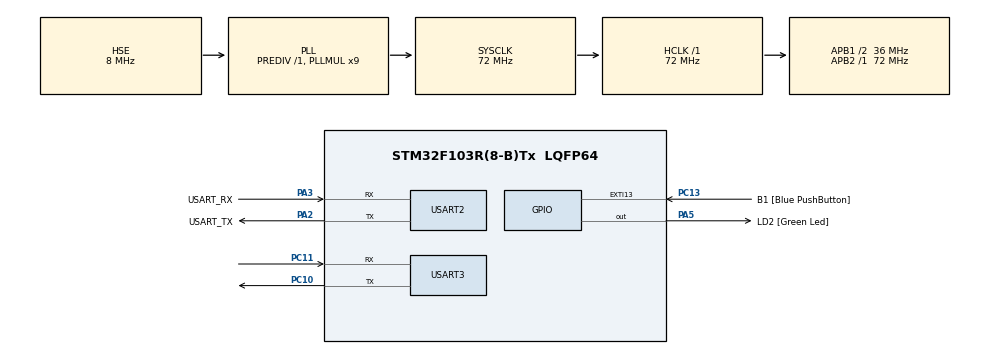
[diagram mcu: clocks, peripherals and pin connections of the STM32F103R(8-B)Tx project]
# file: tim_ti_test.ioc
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Dma.Request0=USART3_RX
Dma.Request1=USART3_TX
Dma.USART3_RX.0.Direction=DMA_PERIPH_TO_MEMORY
Dma.USART3_RX.0.Instance=DMA1_Channel3
Dma.USART3_RX.0.MemDataAlignment=DMA_MDATAALIGN_BYTE
Dma.USART3_RX.0.MemInc=DMA_MINC_ENABLE
Dma.USART3_RX.0.Mode=DMA_NORMAL
Dma.USART3_RX.0.PeriphDataAlignment=DMA_PDATAALIGN_BYTE
Dma.USART3_RX.0.PeriphInc=DMA_PINC_DISABLE
Dma.USART3_RX.0.Priority=DMA_PRIORITY_LOW
Dma.USART3_TX.1.Direction=DMA_MEMORY_TO_PERIPH
Dma.USART3_TX.1.Instance=DMA1_Channel2
Dma.USART3_TX.1.MemDataAlignment=DMA_MDATAALIGN_BYTE
Dma.USART3_TX.1.MemInc=DMA_MINC_ENABLE
Dma.USART3_TX.1.Mode=DMA_NORMAL
Dma.USART3_TX.1.PeriphDataAlignment=DMA_PDATAALIGN_BYTE
Dma.USART3_TX.1.PeriphInc=DMA_PINC_DISABLE
Dma.USART3_TX.1.Priority=DMA_PRIORITY_LOW
Mcu.Family=STM32F1
Mcu.Name=STM32F103R(8-B)Tx
Mcu.Package=LQFP64
NVIC.DMA1_Channel2_IRQn=true\:0\:0\:false\:false\:true\:false
NVIC.DMA1_Channel3_IRQn=true\:0\:0\:false\:false\:true\:false
NVIC.EXTI15_10_IRQn=true\:0\:0\:false\:false\:true\:true
NVIC.PriorityGroup=NVIC_PRIORITYGROUP_4
NVIC.TIM1_UP_IRQn=true\:0\:0\:false\:false\:true\:true
NVIC.USART3_IRQn=true\:0\:0\:false\:false\:true\:true
PA13.GPIO_Label=TMS
PA13.Mode=Serial_Wire
PA13.Signal=SYS_JTMS-SWDIO
PA14.GPIO_Label=TCK
PA14.Mode=Serial_Wire
PA14.Signal=SYS_JTCK-SWCLK
PA2.GPIO_Label=USART_TX
PA2.GPIO_Mode=GPIO_MODE_AF_PP
PA2.GPIO_PuPd=GPIO_NOPULL
PA2.GPIO_Speed=GPIO_SPEED_FREQ_LOW
PA2.Mode=Asynchronous
PA2.Signal=USART2_TX
PA3.GPIO_Label=USART_RX
PA3.GPIO_Mode=GPIO_MODE_AF_PP
PA3.GPIO_PuPd=GPIO_NOPULL
PA3.GPIO_Speed=GPIO_SPEED_FREQ_LOW
PA3.Mode=Asynchronous
PA3.Signal=USART2_RX
PA5.GPIO_Label=LD2 [Green Led]
PA5.GPIO_ModeDefaultOutputPP=GPIO_MODE_OUTPUT_PP
PA5.GPIO_PuPd=GPIO_NOPULL
PA5.GPIO_Speed=GPIO_SPEED_FREQ_LOW
PA5.Signal=GPIO_Output
PB3.GPIO_Label=SWO
PB3.Signal=SYS_JTDO-TRACESWO
PC10.Mode=Asynchronous
PC10.Signal=USART3_TX
PC11.Mode=Asynchronous
PC11.Signal=USART3_RX
PC13-TAMPER-RTC.GPIO_Label=B1 [Blue PushButton]
PC13-TAMPER-RTC.GPIO_PuPd=GPIO_NOPULL
PC13-TAMPER-RTC.Signal=GPXTI13
PC14-OSC32_IN.Mode=LSE-External-Oscillator
PC14-OSC32_IN.Signal=RCC_OSC32_IN
PC15-OSC32_OUT.Mode=LSE-External-Oscillator
PC15-OSC32_OUT.Signal=RCC_OSC32_OUT
PD0-OSC_IN.Mode=HSE-External-Clock-Source
PD0-OSC_IN.Signal=RCC_OSC_IN
PD1-OSC_OUT.Mode=HSE-External-Clock-Source
PD1-OSC_OUT.Signal=RCC_OSC_OUT
ProjectManager.HeapSize=0x200
ProjectManager.StackSize=0x400
ProjectManager.TargetToolchain=MDK-ARM V5
RCC.AHBFreq_Value=72000000
RCC.APB1CLKDivider=RCC_HCLK_DIV2
RCC.APB1Freq_Value=36000000
RCC.APB1TimFreq_Value=72000000
RCC.APB2Freq_Value=72000000
RCC.APB2TimFreq_Value=72000000
RCC.HCLKFreq_Value=72000000
RCC.PLLMUL=RCC_PLL_MUL9
RCC.PLLSourceVirtual=RCC_PLLSOURCE_HSE
RCC.RTCClockSelection=RCC_RTCCLKSOURCE_LSE
RCC.SYSCLKFreq_VALUE=72000000
RCC.SYSCLKSource=RCC_SYSCLKSOURCE_PLLCLK
RCC.USBFreq_Value=72000000
TIM1.Period=10000-1
TIM1.Prescaler=72-1
TIM1.RepetitionCounter=100
USART2.VirtualMode=VM_ASYNC
USART3.VirtualMode=VM_ASYNC
VP_TIM1_VS_ClockSourceINT.Mode=Internal
board=NUCLEO-F103RB

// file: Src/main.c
/**
  ******************************************************************************
  * @file           : main.c
  * @brief          : Main program body
  ******************************************************************************
  ** This notice applies to any and all portions of this file
  * that are not between comment pairs USER CODE BEGIN and
  * USER CODE END. Other portions of this file, whether
  * inserted by the user or by software development tools
  * are owned by their respective copyright owners.
  *
  * COPYRIGHT(c) 2018 STMicroelectronics
  *
  * Redistribution and use in source and binary forms, with or without modification,
  * are permitted provided that the following conditions are met:
  *   1. Redistributions of source code must retain the above copyright notice,
  *      this list of conditions and the following disclaimer.
  *   2. Redistributions in binary form must reproduce the above copyright notice,
  *      this list of conditions and the following disclaimer in the documentation
  *      and/or other materials provided with the distribution.
  *   3. Neither the name of STMicroelectronics nor the names of its contributors
  *      may be used to endorse or promote products derived from this software
  *      without specific prior written permission.
  *
  * THIS SOFTWARE IS PROVIDED BY THE COPYRIGHT HOLDERS AND CONTRIBUTORS "AS IS"
  * AND ANY EXPRESS OR IMPLIED WARRANTIES, INCLUDING, BUT NOT LIMITED TO, THE
  * IMPLIED WARRANTIES OF MERCHANTABILITY AND FITNESS FOR A PARTICULAR PURPOSE ARE
  * DISCLAIMED. IN NO EVENT SHALL THE COPYRIGHT HOLDER OR CONTRIBUTORS BE LIABLE
  * FOR ANY DIRECT, INDIRECT, INCIDENTAL, SPECIAL, EXEMPLARY, OR CONSEQUENTIAL
  * DAMAGES (INCLUDING, BUT NOT LIMITED TO, PROCUREMENT OF SUBSTITUTE GOODS OR
  * SERVICES; LOSS OF USE, DATA, OR PROFITS; OR BUSINESS INTERRUPTION) HOWEVER
  * CAUSED AND ON ANY THEORY OF LIABILITY, WHETHER IN CONTRACT, STRICT LIABILITY,
  * OR TORT (INCLUDING NEGLIGENCE OR OTHERWISE) ARISING IN ANY WAY OUT OF THE USE
  * OF THIS SOFTWARE, EVEN IF ADVISED OF THE POSSIBILITY OF SUCH DAMAGE.
  *
  ******************************************************************************
  */
#include "main.h"
#include "stm32f1xx_hal.h"
#include "dma.h"
#include "tim.h"
#include "usart.h"
#include "gpio.h"

/* USER CODE BEGIN PV */
/* Private variables ---------------------------------------------------------*/

/* USER CODE END PV */

void SystemClock_Config(void);

/* USER CODE BEGIN PFP */
/* Private function prototypes -----------------------------------------------*/

/* USER CODE END PFP */

/* USER CODE BEGIN 0 */
int fputc(int ch, FILE *f)
{
    HAL_UART_Transmit(&huart2,(uint8_t *)&ch,1,0xff);
    return ch;
}

/* USER CODE END 0 */

int main(void)
{

  /* MCU Configuration----------------------------------------------------------*/

  /* Reset of all peripherals, Initializes the Flash interface and the Systick. */
  HAL_Init();

  /* Configure the system clock */
  SystemClock_Config();

  /* Initialize all configured peripherals */
  MX_GPIO_Init();
  MX_DMA_Init();
  MX_USART2_UART_Init();
  MX_TIM1_Init();
  MX_USART3_UART_Init();
  /* USER CODE BEGIN 2 */
  __HAL_UART_ENABLE_IT(&huart3,UART_IT_IDLE);
  HAL_UART_Receive_DMA(&huart3,rx_buffer,BUFFER_SIZE);

  /* USER CODE END 2 */

  /* Infinite loop */
  /* USER CODE BEGIN WHILE */
  HAL_TIM_Base_Start_IT(&htim1);
  while (1)
  {

  /* USER CODE END WHILE */

  /* USER CODE BEGIN 3 */
  if(recv_end_flag == 1){
      HAL_UART_Transmit_DMA(&huart3,rx_buffer,50);
      recv_end_flag = 0;
      HAL_UART_Receive_DMA(&huart3,rx_buffer,BUFFER_SIZE);
  }

  }
  /* USER CODE END 3 */

}

void SystemClock_Config(void)
{

  RCC_OscInitTypeDef RCC_OscInitStruct;
  RCC_ClkInitTypeDef RCC_ClkInitStruct;

    /**Initializes the CPU, AHB and APB busses clocks
    */
  RCC_OscInitStruct.OscillatorType = RCC_OSCILLATORTYPE_HSE;
  RCC_OscInitStruct.HSEState = RCC_HSE_BYPASS;
  RCC_OscInitStruct.HSEPredivValue = RCC_HSE_PREDIV_DIV1;
  RCC_OscInitStruct.HSIState = RCC_HSI_ON;
  RCC_OscInitStruct.PLL.PLLState = RCC_PLL_ON;
  RCC_OscInitStruct.PLL.PLLSource = RCC_PLLSOURCE_HSE;
  RCC_OscInitStruct.PLL.PLLMUL = RCC_PLL_MUL9;
  if (HAL_RCC_OscConfig(&RCC_OscInitStruct) != HAL_OK)
  {
    _Error_Handler(__FILE__, __LINE__);
  }

    /**Initializes the CPU, AHB and APB busses clocks
    */
  RCC_ClkInitStruct.ClockType = RCC_CLOCKTYPE_HCLK|RCC_CLOCKTYPE_SYSCLK
                              |RCC_CLOCKTYPE_PCLK1|RCC_CLOCKTYPE_PCLK2;
  RCC_ClkInitStruct.SYSCLKSource = RCC_SYSCLKSOURCE_PLLCLK;
  RCC_ClkInitStruct.AHBCLKDivider = RCC_SYSCLK_DIV1;
  RCC_ClkInitStruct.APB1CLKDivider = RCC_HCLK_DIV2;
  RCC_ClkInitStruct.APB2CLKDivider = RCC_HCLK_DIV1;

  if (HAL_RCC_ClockConfig(&RCC_ClkInitStruct, FLASH_LATENCY_2) != HAL_OK)
  {
    _Error_Handler(__FILE__, __LINE__);
  }

    /**Configure the Systick interrupt time
    */
  HAL_SYSTICK_Config(HAL_RCC_GetHCLKFreq()/1000);

    /**Configure the Systick
    */
  HAL_SYSTICK_CLKSourceConfig(SYSTICK_CLKSOURCE_HCLK);

  /* SysTick_IRQn interrupt configuration */
  HAL_NVIC_SetPriority(SysTick_IRQn, 0, 0);
}

void _Error_Handler(char *file, int line)
{
  while(1)
  {
  }
}

/************************ (C) COPYRIGHT STMicroelectronics *****END OF FILE****/
